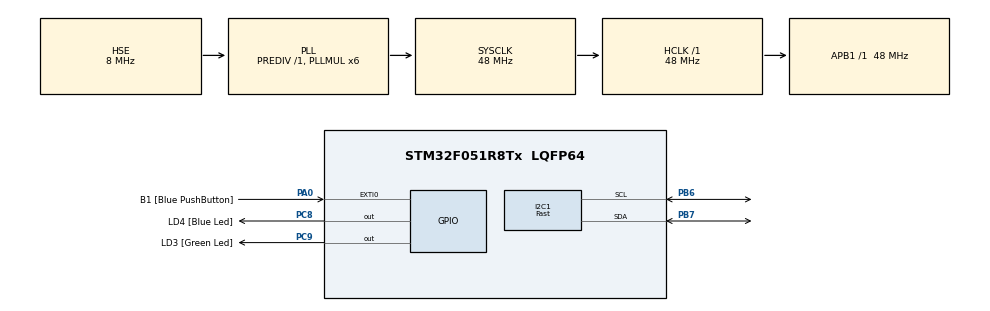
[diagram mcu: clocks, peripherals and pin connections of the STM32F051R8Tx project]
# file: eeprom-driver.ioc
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Mcu.Family=STM32F0
RCC.PLLSourceVirtual=RCC_PLLSOURCE_HSE
I2C1.I2C_Speed_Mode=I2C_Fast
PC9.GPIO_Label=LD3 [Green Led]
PA14.GPIO_Label=SWCLK
PA0.GPIO_Label=B1 [Blue PushButton]
PC8.Signal=GPIO_Output
RCC.SYSCLKSource=RCC_SYSCLKSOURCE_PLLCLK
ProjectManager.StackSize=0x400
PC8.GPIO_Label=LD4 [Blue Led]
PA13.Signal=SYS_SWDIO
ProjectManager.TargetToolchain=STM32CubeIDE
RCC.HCLKFreq_Value=48000000
PB6.Signal=I2C1_SCL
I2C1.Timing=0x0000020B
PB6.Mode=I2C
RCC.AHBFreq_Value=48000000
PF0-OSC_IN.Mode=HSE-External-Clock-Source
board=STM32F0DISCOVERY
RCC.PLLMUL=RCC_PLL_MUL6
PA0.GPIO_ModeDefaultEXTI=GPIO_MODE_EVT_RISING
PB7.Signal=I2C1_SDA
Mcu.Name=STM32F051R8Tx
PA13.GPIO_Label=SWDIO
PA0.Signal=GPXTI0
RCC.SYSCLKFreq_VALUE=48000000
Mcu.Package=LQFP64
PB7.Mode=I2C
PA14.Signal=SYS_SWCLK
ProjectManager.HeapSize=0x200
RCC.APB1TimFreq_Value=48000000
PC9.Signal=GPIO_Output
PF0-OSC_IN.Signal=RCC_OSC_IN
RCC.APB1Freq_Value=48000000

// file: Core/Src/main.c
/* USER CODE BEGIN Header */
/**
  ******************************************************************************
  * @file           : main.c
  * @brief          : Main program body
  ******************************************************************************
  * @attention
  *
  * <h2><center>&copy; Copyright (c) 2022 STMicroelectronics.
  * All rights reserved.</center></h2>
  *
  * This software component is licensed by ST under BSD 3-Clause license,
  * the "License"; You may not use this file except in compliance with the
  * License. You may obtain a copy of the License at:
  *                        opensource.org/licenses/BSD-3-Clause
  *
  ******************************************************************************
  */
/* USER CODE END Header */
#include "main.h"
#include "eeprom.h"
#include "stdint.h"
#include "string.h"

I2C_HandleTypeDef hi2c1;

void SystemClock_Config(void);
static void MX_GPIO_Init(void);
static void MX_I2C1_Init(void);

int main(void)
{
  /* USER CODE BEGIN 1 */

	char buffer []= "Testing EEPROM Library";

	uint8_t readbuffer[100];

	uint8_t writebuffer[100];

	uint8_t dataw[] ="Hello world";
  /* USER CODE END 1 */

  /* MCU Configuration--------------------------------------------------------*/

  /* Reset of all peripherals, Initializes the Flash interface and the Systick. */
  HAL_Init();

  /* Configure the system clock */
  SystemClock_Config();

  /* Initialize all configured peripherals */
  MX_GPIO_Init();
  MX_I2C1_Init();
  /* USER CODE BEGIN 2 */

  for(int i = 0; i < 512; i++)
  {
	  EEPROM_Page_Erease(i);
  }
  /*
  for(int i = 0; i<100;i++)
  {
	  writebuffer[i] = i +10;
  }
  */

  EEPROM_Write(3, 10, dataw, strlen(dataw));
  EEPROM_Read(3, 0, readbuffer, 100);

  /* USER CODE END 2 */

  /* Infinite loop */
  while (1)
  {

  }
}

void SystemClock_Config(void)
{
  RCC_OscInitTypeDef RCC_OscInitStruct = {0};
  RCC_ClkInitTypeDef RCC_ClkInitStruct = {0};
  RCC_PeriphCLKInitTypeDef PeriphClkInit = {0};

  /** Initializes the RCC Oscillators according to the specified parameters
  * in the RCC_OscInitTypeDef structure.
  */
  RCC_OscInitStruct.OscillatorType = RCC_OSCILLATORTYPE_HSI|RCC_OSCILLATORTYPE_HSE;
  RCC_OscInitStruct.HSEState = RCC_HSE_BYPASS;
  RCC_OscInitStruct.HSIState = RCC_HSI_ON;
  RCC_OscInitStruct.HSICalibrationValue = RCC_HSICALIBRATION_DEFAULT;
  RCC_OscInitStruct.PLL.PLLState = RCC_PLL_ON;
  RCC_OscInitStruct.PLL.PLLSource = RCC_PLLSOURCE_HSE;
  RCC_OscInitStruct.PLL.PLLMUL = RCC_PLL_MUL6;
  RCC_OscInitStruct.PLL.PREDIV = RCC_PREDIV_DIV1;
  if (HAL_RCC_OscConfig(&RCC_OscInitStruct) != HAL_OK)
  {
    Error_Handler();
  }
  /** Initializes the CPU, AHB and APB buses clocks
  */
  RCC_ClkInitStruct.ClockType = RCC_CLOCKTYPE_HCLK|RCC_CLOCKTYPE_SYSCLK
                              |RCC_CLOCKTYPE_PCLK1;
  RCC_ClkInitStruct.SYSCLKSource = RCC_SYSCLKSOURCE_PLLCLK;
  RCC_ClkInitStruct.AHBCLKDivider = RCC_SYSCLK_DIV1;
  RCC_ClkInitStruct.APB1CLKDivider = RCC_HCLK_DIV1;

  if (HAL_RCC_ClockConfig(&RCC_ClkInitStruct, FLASH_LATENCY_1) != HAL_OK)
  {
    Error_Handler();
  }
  PeriphClkInit.PeriphClockSelection = RCC_PERIPHCLK_I2C1;
  PeriphClkInit.I2c1ClockSelection = RCC_I2C1CLKSOURCE_HSI;
  if (HAL_RCCEx_PeriphCLKConfig(&PeriphClkInit) != HAL_OK)
  {
    Error_Handler();
  }
}

static void MX_I2C1_Init(void)
{

  hi2c1.Instance = I2C1;
  hi2c1.Init.Timing = 0x0000020B;
  hi2c1.Init.OwnAddress1 = 0;
  hi2c1.Init.AddressingMode = I2C_ADDRESSINGMODE_7BIT;
  hi2c1.Init.DualAddressMode = I2C_DUALADDRESS_DISABLE;
  hi2c1.Init.OwnAddress2 = 0;
  hi2c1.Init.OwnAddress2Masks = I2C_OA2_NOMASK;
  hi2c1.Init.GeneralCallMode = I2C_GENERALCALL_DISABLE;
  hi2c1.Init.NoStretchMode = I2C_NOSTRETCH_DISABLE;
  if (HAL_I2C_Init(&hi2c1) != HAL_OK)
  {
    Error_Handler();
  }
  /** Configure Analogue filter
  */
  if (HAL_I2CEx_ConfigAnalogFilter(&hi2c1, I2C_ANALOGFILTER_ENABLE) != HAL_OK)
  {
    Error_Handler();
  }
  /** Configure Digital filter
  */
  if (HAL_I2CEx_ConfigDigitalFilter(&hi2c1, 0) != HAL_OK)
  {
    Error_Handler();
  }

}

static void MX_GPIO_Init(void)
{
  GPIO_InitTypeDef GPIO_InitStruct = {0};

  /* GPIO Ports Clock Enable */
  __HAL_RCC_GPIOF_CLK_ENABLE();
  __HAL_RCC_GPIOA_CLK_ENABLE();
  __HAL_RCC_GPIOC_CLK_ENABLE();
  __HAL_RCC_GPIOB_CLK_ENABLE();

  /*Configure GPIO pin Output Level */
  HAL_GPIO_WritePin(GPIOC, LD4_Pin|LD3_Pin, GPIO_PIN_RESET);

  /*Configure GPIO pin : B1_Pin */
  GPIO_InitStruct.Pin = B1_Pin;
  GPIO_InitStruct.Mode = GPIO_MODE_EVT_RISING;
  GPIO_InitStruct.Pull = GPIO_NOPULL;
  HAL_GPIO_Init(B1_GPIO_Port, &GPIO_InitStruct);

  /*Configure GPIO pins : LD4_Pin LD3_Pin */
  GPIO_InitStruct.Pin = LD4_Pin|LD3_Pin;
  GPIO_InitStruct.Mode = GPIO_MODE_OUTPUT_PP;
  GPIO_InitStruct.Pull = GPIO_NOPULL;
  GPIO_InitStruct.Speed = GPIO_SPEED_FREQ_LOW;
  HAL_GPIO_Init(GPIOC, &GPIO_InitStruct);

}

void Error_Handler(void)
{
  __disable_irq();
  while (1)
  {
  }
}

/************************ (C) COPYRIGHT STMicroelectronics *****END OF FILE****/
